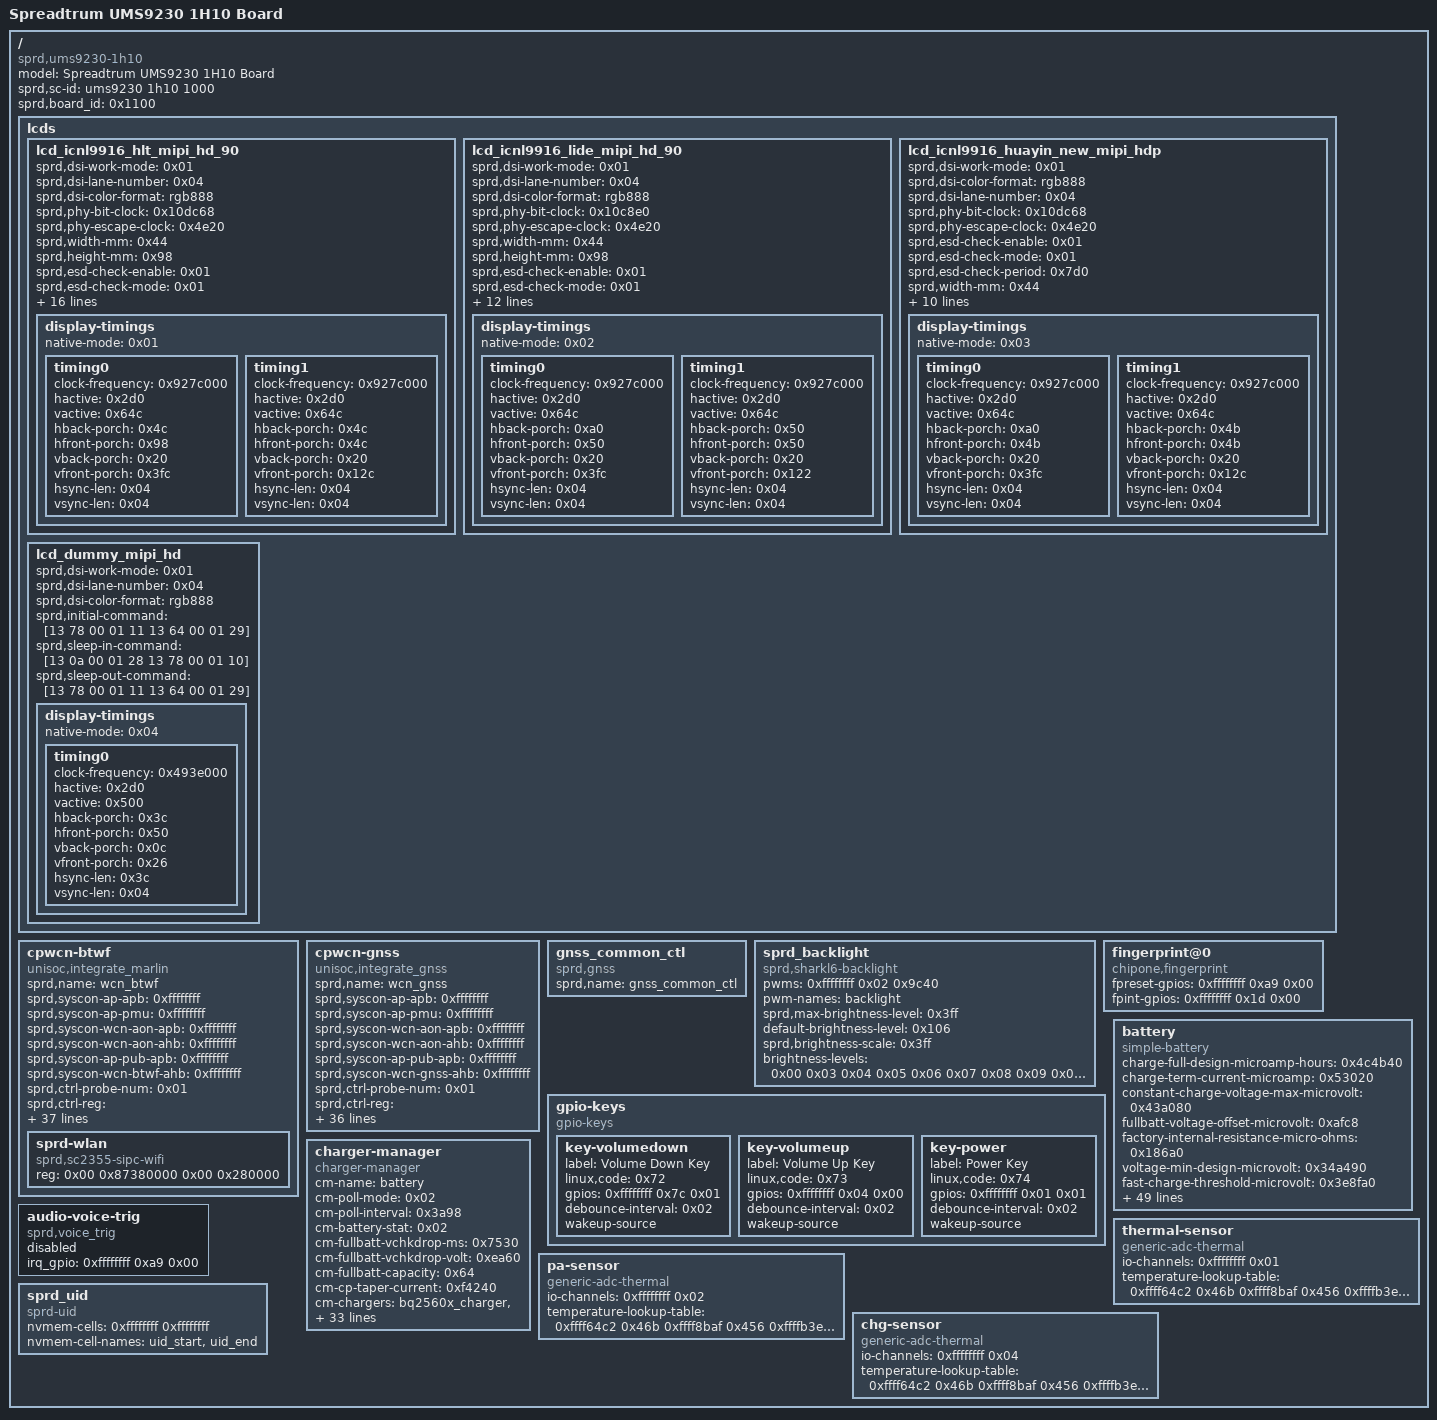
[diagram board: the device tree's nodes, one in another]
/dts-v1/;

/ {
	model = "Spreadtrum UMS9230 1H10 Board";
	compatible = "sprd,ums9230-1h10";
	sprd,sc-id = "ums9230 1h10 1000";
	sprd,board_id = <0x1100>;

	fragment {
		target-path = "/";

		__overlay__ {
			#address-cells = <0x02>;
			#size-cells = <0x02>;

			lcds {

				lcd_icnl9916_hlt_mipi_hd_90 {
					sprd,dsi-work-mode = <0x01>;
					sprd,dsi-lane-number = <0x04>;
					sprd,dsi-color-format = "rgb888";
					sprd,phy-bit-clock = <0x10dc68>;
					sprd,phy-escape-clock = <0x4e20>;
					sprd,width-mm = <0x44>;
					sprd,height-mm = <0x98>;
					sprd,esd-check-enable = <0x01>;
					sprd,esd-check-mode = <0x01>;
					sprd,esd-check-period = <0x3e8>;
					sprd,lcd-id-register = [a1];
					sprd,lcd-id-value-len = <0x01>;
					sprd,lcd-id-value = [99];
					sprd,lcd-id-tokernel = <0x9901>;
					sprd,lcd-id-adc-min = <0x1f4>;
					sprd,lcd-id-adc-max = <0x320>;
					sprd,reset-on-sequence = <0x01 0x05 0x00 0x05 0x01 0x78>;
					sprd,reset-off-sequence = <0x00 0x14>;
					sprd,initial-command = [39 00 00 04 f0 99 16 0c 39 00 00 15 c1 10 20 20 2c 04 30 30 04 4c 06 22 70 35 20 07 11 84 4c 00 93 39 00 00 07 c3 06 00 ff 00 ff 4d 39 00 00 0d c4 04 32 b8 40 00 bc 00 00 00 00 00 f0 39 00 00 18 c5 03 21 96 c8 3e 00 04 01 14 04 0e 1f c6 03 64 ff 01 04 18 22 45 14 38 39 00 00 0e c6 89 24 17 2b 2b 28 3f 03 16 16 00 00 00 39 00 00 1e b2 03 02 97 98 99 99 8b 01 49 65 71 65 71 65 71 65 71 65 71 65 71 00 00 00 55 55 00 00 00 39 00 00 1a b3 f3 01 02 15 95 89 00 00 7f 00 00 00 00 08 44 f3 01 01 01 01 00 00 00 00 00 39 00 00 21 b5 00 04 06 00 00 00 00 00 00 c1 00 2a 1a 18 16 14 12 10 0e 0c 0a 28 60 ff fc 00 00 00 00 00 00 00 39 00 00 21 b6 00 05 07 00 00 00 00 00 00 c1 00 2b 1b 19 17 15 13 11 0f 0d 0b 29 60 ff fc 00 00 00 00 00 00 00 39 00 00 17 b7 0a 0a 0a 0a 0a 0a 0a 0a 0a 0a 0a 0a 0a 0a 0a 0a 0a 0a 0a 0a 0a 0a 39 00 00 14 bc 00 00 00 00 04 00 ff f0 0b 33 5c 5b 33 33 00 64 3c 5e 36 39 00 00 0a bf 0c 19 0c 19 00 11 04 18 50 39 00 00 15 c0 40 93 ff ff ff 3f ff 00 ff 00 cc b1 23 45 67 89 ad ff ff f0 39 00 00 21 c7 76 54 32 22 23 45 67 76 30 76 54 32 22 23 45 67 76 30 31 00 01 ff ff 40 6e 6e 40 00 00 00 00 00 39 00 00 21 80 ff f9 ee e7 e0 d8 d6 d2 ce c2 ba b2 ab a5 9f 95 8c 85 7d 7d 74 6b 60 54 46 32 28 1c 19 15 11 0e 39 00 00 21 81 ff f9 ee e7 e0 d8 d6 d2 ce c2 ba b2 ab a5 9f 95 8c 85 7d 7d 74 6b 60 54 46 32 28 1c 19 15 11 0e 39 00 00 21 82 ff f9 ee e7 e0 d8 d6 d2 ce c2 ba b2 ab a5 9f 95 8c 85 7d 7d 74 6b 60 54 46 32 28 1c 19 15 11 0e 39 00 00 1a 83 01 0a 05 01 00 0a 05 01 00 0a 05 01 00 0a 06 02 00 0a 06 02 00 0a 06 02 00 39 00 00 1c 84 28 85 b2 da d8 4b 61 3c 70 07 e0 b2 da d8 4b 61 3c 70 07 e0 b2 da d8 4b 61 3c 70 15 00 00 0b c2 11 65 01 10 00 01 80 02 21 43 15 00 00 02 ca 01 39 00 00 04 f0 00 00 00 39 00 00 03 35 00 00 39 78 00 03 11 00 00 39 32 00 03 29 00 00 39 00 00 03 6d 02 00];
					sprd,sleep-in-command = [23 00 00 02 26 08 23 23 00 02 28 00 23 78 00 02 10 00];
					sprd,sleep-out-command = [23 78 00 02 11 00 23 23 00 02 29 00 23 00 00 02 26 01];
					phandle = <0x15>;

					display-timings {
						native-mode = <0x01>;

						timing0 {
							clock-frequency = <0x927c000>;
							hactive = <0x2d0>;
							vactive = <0x64c>;
							hback-porch = <0x4c>;
							hfront-porch = <0x98>;
							vback-porch = <0x20>;
							vfront-porch = <0x3fc>;
							hsync-len = <0x04>;
							vsync-len = <0x04>;
							phandle = <0x01>;
						};

						timing1 {
							clock-frequency = <0x927c000>;
							hactive = <0x2d0>;
							vactive = <0x64c>;
							hback-porch = <0x4c>;
							hfront-porch = <0x4c>;
							vback-porch = <0x20>;
							vfront-porch = <0x12c>;
							hsync-len = <0x04>;
							vsync-len = <0x04>;
							phandle = <0x16>;
						};
					};
				};

				lcd_icnl9916_lide_mipi_hd_90 {
					sprd,dsi-work-mode = <0x01>;
					sprd,dsi-lane-number = <0x04>;
					sprd,dsi-color-format = "rgb888";
					sprd,phy-bit-clock = <0x10c8e0>;
					sprd,phy-escape-clock = <0x4e20>;
					sprd,width-mm = <0x44>;
					sprd,height-mm = <0x98>;
					sprd,esd-check-enable = <0x01>;
					sprd,esd-check-mode = <0x01>;
					sprd,esd-check-period = <0x3e8>;
					sprd,reset-on-sequence = <0x01 0x05 0x00 0x0a 0x01 0x1e>;
					sprd,reset-off-sequence = <0x01 0x14>;
					sprd,initial-command = <0x39000003 0xf05a5939 0x3f1 0xa5a62300 0x2d431 0x39000005 0xc0409300 0x1f390000 0x21c11020 0x25220450 0x50044c06 0x22703030 0x711844c 0x931363 0x00 0x00 0x2300 0x2c200 0x39000009 0xc30600ff 0xff404d 0x1390000 0x21c40433 0xb840c0bc 0xa00000 0x264891 0xb3750004 0xe020f000 0x00 0x00 0x3900 0x21c503 0x2396c832 0x50212 0xc04323f 0x801100c 0x18c8000a 0x14011438 0x7f000000 0x39 0x21c6 0x8924172b 0x2b283f03 0x16160001 0x40009898 0x60801b00 0x00 0x00 0x00 0x39000021 0xca3d4001 0x19469441 0x8f33114a 0x5e2c4050 0x64324633 0x1010a 0x2220005 0x5032 0x4390000 0x21b28182 0x85864444 0x1019968 0x68686868 0x68686868 0x68686801 0x1010055 0x55102011 0x3900 0x21b3f2 0x1020581 0x68010168 0x1000008 0x4400008a 0xaa800000 0x00 0xffff0 0x39 0x21b6 0x282a00 0x00 0xc100 0x1a181614 0x12100e0c 0xa04607f 0xfc000000 0x00 0x39000021 0xb700292b 0x00 0xc1 0x1b1917 0x1513110f 0xd0b0560 0x7ffc0000 0x00 0x390000 0x21b90055 0x55555555 0x55555555 0x555550aa 0xaaaaaaaa 0xa0aaaaaa 0xaaaaa000 0x00 0x3900 0x9bb01 0x2030a04 0x13145239 0x21bc 0x00 0x400fff0 0xb33505b 0x33330000 0x00 0x00 0x00 0x00 0x39000007 0xbda1a252 0x2e008f39 0x11be 0xc884338 0x33000038 0xb2afb2 0xaf000033 0x3900000a 0xbf0c190c 0x19001104 0x18503900 0x21c776 0x54322223 0x45677630 0x76543222 0x23456776 0x30310001 0xffff00dc 0xdc400000 0x39 0x3fb 0x4a2c3900 0x3f0a5 0xa6390000 0x3f15a59 0x39000003 0x35000039 0x78000311 0x390a 0x32900 0x390000 0x36d0200>;
					sprd,vref-command = [39 00 00 03 f0 5a 59 39 00 00 03 f1 a5 a6 39 00 00 09 bb 01 02 03 0a 04 13 14 52];
					sprd,sleep-in-command = <0x39000003 0xf05a5939 0x3f1 0xa5a63900 0x9bb01 0x2030a04 0x13140039 0x36d 0x2500390a 0x32800 0x397800 0x3100000>;
					sprd,sleep-out-command = [39 00 00 03 f0 5a 59 39 00 00 03 f1 a5 a6 39 78 00 03 11 00 00 39 32 00 03 29 00 00 39 00 00 03 6d 02 00];
					phandle = <0x17>;

					display-timings {
						native-mode = <0x02>;

						timing0 {
							clock-frequency = <0x927c000>;
							hactive = <0x2d0>;
							vactive = <0x64c>;
							hback-porch = <0xa0>;
							hfront-porch = <0x50>;
							vback-porch = <0x20>;
							vfront-porch = <0x3fc>;
							hsync-len = <0x04>;
							vsync-len = <0x04>;
							phandle = <0x02>;
						};

						timing1 {
							clock-frequency = <0x927c000>;
							hactive = <0x2d0>;
							vactive = <0x64c>;
							hback-porch = <0x50>;
							hfront-porch = <0x50>;
							vback-porch = <0x20>;
							vfront-porch = <0x122>;
							hsync-len = <0x04>;
							vsync-len = <0x04>;
							phandle = <0x18>;
						};
					};
				};

				lcd_icnl9916_huayin_new_mipi_hdp {
					sprd,dsi-work-mode = <0x01>;
					sprd,dsi-color-format = "rgb888";
					sprd,dsi-lane-number = <0x04>;
					sprd,phy-bit-clock = <0x10dc68>;
					sprd,phy-escape-clock = <0x4e20>;
					sprd,esd-check-enable = <0x01>;
					sprd,esd-check-mode = <0x01>;
					sprd,esd-check-period = <0x7d0>;
					sprd,width-mm = <0x44>;
					sprd,height-mm = <0x97>;
					sprd,reset-on-sequence = <0x01 0x05 0x00 0x0a 0x01 0x14>;
					sprd,reset-off-sequence = <0x01 0x0a>;
					sprd,initial-command = <0x39000003 0xf05a5939 0x3f1 0xa5a63900 0x2d431 0x39000005 0xc0409300 0x1f390000 0x21c11020 0x202c044b 0x4b044c06 0x22703020 0x711844c 0x931363 0x00 0x00 0x3900 0x2c200 0x39000009 0xc30600ff 0xff404d 0x1390000 0x21c40433 0xb840c0bc 0xa00000 0x264891 0xb3750004 0xe020f000 0x00 0x00 0x3900 0x21c503 0x2396c832 0x50212 0xc04323f 0x801100c 0x1fc8000a 0x14011438 0x7f000000 0x39 0x21c6 0x8924172b 0x2b283f03 0x16160001 0x40009898 0x60801b00 0x00 0x00 0x00 0x39000021 0xca014000 0x19469441 0x8f331150 0x505a5a64 0x64323211 0x1010a 0x5220005 0x643c 0x4390000 0x21b20302 0x97989999 0x8b014965 0x71657165 0x71657165 0x71657100 0x55 0x55102011 0x3900 0xcb3f3 0x1011595 0x76000071 0x3900 0x21b600 0x4060000 0x00 0xc1002a1a 0x18161412 0x100e0c0a 0x2860fffc 0x00 0x39 0x21b7 0x50700 0x00 0xc1002b 0x1b191715 0x13110f0d 0xb2960ff 0xfc000000 0x00 0x39000021 0xb9005555 0x55555555 0x55555555 0x5550aaaa 0xaaaaaaa0 0xaaaaaaaa 0xaaa00000 0x00 0x390000 0x9bb0102 0x30a0413 0x14523900 0x21bc00 0x04 0xfff00b 0x33505b33 0x33000000 0x00 0x00 0x00 0x39 0x7bd 0xa1a2522e 0x8f3900 0x11be0c 0x88433833 0x3800 0xb2afb2af 0x3339 0xabf 0xc190c19 0x110418 0x50390000 0x21c77654 0x32222345 0x67763076 0x54322223 0x45677630 0x310001ff 0xff00dcdc 0x40000000 0x3900 0x2180ff 0xf6eae2db 0xd6d1cdc9 0xbeb5a599 0x8f877f76 0x756c6359 0x4e402e24 0x1916130f 0xc080439 0x2181 0xfff6eae2 0xdbd6d1cd 0xc9beb5a5 0x998f877f 0x76756c63 0x594e402e 0x24191613 0xf0c0804 0x39000021 0x82fff6ea 0xe2dbd6d1 0xcdc9beb5 0xa5998f87 0x7f76756c 0x63594e40 0x2e241916 0x130f0c08 0x4390000 0xe830101 0x10001 0x20002 0x20039 0x1c84 0x1489c3a6 0x7a90a4a9 0x701489c3 0xa67a90a4 0xa9701489 0xc3a67a90 0xa4a97039 0x3fb 0x5e403900 0x4c847 0x483900 0x33500 0x390000 0x3f15a59 0x39000003 0xf0a5a639 0x78000311 0x390a 0x32900 0x390000 0x36d0200>;
					sprd,sleep-in-command = [39 00 00 03 f0 5a 59 39 00 00 03 f1 a5 a6 39 00 00 09 bb 01 02 03 0a 04 13 14 00 39 00 00 03 f1 5a 59 39 00 00 03 f0 a5 a6 39 00 00 03 6d 25 00 39 0a 00 03 28 00 00 39 78 00 03 10 00 00];
					sprd,sleep-out-command = [39 78 00 03 11 00 00 39 0a 00 03 29 00 00 39 00 00 03 6d 02 00];
					phandle = <0x19>;

					display-timings {
						native-mode = <0x03>;

						timing0 {
							clock-frequency = <0x927c000>;
							hactive = <0x2d0>;
							vactive = <0x64c>;
							hback-porch = <0xa0>;
							hfront-porch = <0x4b>;
							vback-porch = <0x20>;
							vfront-porch = <0x3fc>;
							hsync-len = <0x04>;
							vsync-len = <0x04>;
							phandle = <0x03>;
						};

						timing1 {
							clock-frequency = <0x927c000>;
							hactive = <0x2d0>;
							vactive = <0x64c>;
							hback-porch = <0x4b>;
							hfront-porch = <0x4b>;
							vback-porch = <0x20>;
							vfront-porch = <0x12c>;
							hsync-len = <0x04>;
							vsync-len = <0x04>;
							phandle = <0x1a>;
						};
					};
				};

				lcd_dummy_mipi_hd {
					sprd,dsi-work-mode = <0x01>;
					sprd,dsi-lane-number = <0x04>;
					sprd,dsi-color-format = "rgb888";
					sprd,initial-command = [13 78 00 01 11 13 64 00 01 29];
					sprd,sleep-in-command = [13 0a 00 01 28 13 78 00 01 10];
					sprd,sleep-out-command = [13 78 00 01 11 13 64 00 01 29];
					phandle = <0x1b>;

					display-timings {
						native-mode = <0x04>;

						timing0 {
							clock-frequency = <0x493e000>;
							hactive = <0x2d0>;
							vactive = <0x500>;
							hback-porch = <0x3c>;
							hfront-porch = <0x50>;
							vback-porch = <0x0c>;
							vfront-porch = <0x26>;
							hsync-len = <0x3c>;
							vsync-len = <0x04>;
							phandle = <0x04>;
						};
					};
				};
			};

			cpwcn-btwf {
				compatible = "unisoc,integrate_marlin";
				sprd,name = "wcn_btwf";
				sprd,syscon-ap-apb = <0xffffffff>;
				sprd,syscon-ap-pmu = <0xffffffff>;
				sprd,syscon-wcn-aon-apb = <0xffffffff>;
				sprd,syscon-wcn-aon-ahb = <0xffffffff>;
				sprd,syscon-ap-pub-apb = <0xffffffff>;
				sprd,syscon-wcn-btwf-ahb = <0xffffffff>;
				sprd,ctrl-probe-num = <0x01>;
				sprd,ctrl-reg = <0x9018 0x23a8 0x2818 0x23a8 0x90 0x98 0x0c 0x1410 0x4c 0x0c>;
				sprd,ctrl-mask = <0x3fff 0x2000000 0x80 0x1000000 0x40000000 0x100f 0x55 0x3000000 0xffffffff 0x55>;
				sprd,ctrl-value = <0x70 0x2000000 0x80 0x1000000 0x40000000 0x00 0x55 0x3000000 0x7fdc00 0x00>;
				sprd,ctrl-rw-offset = <0x1000 0x2000 0x2000 0x2000 0x00 0x00 0x00 0x1000 0x00 0x00>;
				sprd,ctrl-us-delay = <0x3e8 0x3e8 0x3e8 0x7d0 0x3e8 0x3e8 0x3e8 0x3e8 0x3e8 0x3e8>;
				sprd,ctrl-type = <0x02 0x01 0x01 0x01 0x0a 0x0a 0x09 0x07 0x09 0x09>;
				sprd,ctrl-shutdown-reg = <0x98>;
				sprd,ctrl-shutdown-mask = <0x1000>;
				sprd,ctrl-shutdown-value = <0x1000>;
				sprd,ctrl-shutdown-rw-offset = <0x00>;
				sprd,ctrl-shutdown-us-delay = <0x0a>;
				sprd,ctrl-shutdown-type = <0x0a>;
				reg = <0x00 0x87000000 0x00 0x200000 0x00 0x7c00a000 0x00 0x74>;
				sprd,debugbus-to-ddr-disable;
				sprd,wcn-pm-qos-enable;
				sprd,file-name = "/dev/block/platform/soc/soc:ap-apb/201d0000.sdio/by-name/wcnmodem";
				sprd,file-name-ufs = "/dev/block/platform/soc/soc:ap-apb/20200000.ufs/by-name/wcnmodem";
				sprd,firmware-path = "/vendor/firmware/";
				sprd,file-length = <0x200000>;
				sprd,apcp-sync-addr = <0x7fdc00>;
				sprd,wcn-sipc-ver = <0x01>;
				vddwcn-supply = <0xffffffff>;
				dcxo1v8-supply = <0xffffffff>;
				vddwifipa-supply = <0xffffffff>;
				merlion-chip-en-gpios = <0xffffffff 0x76 0x00>;
				merlion-rst-gpios = <0xffffffff 0x75 0x00>;
				xtal-26m-type-sel-gpios = <0xffffffff 0xad 0x00>;
				nvmem-cells = <0xffffffff>;
				nvmem-cell-names = "wcn_efuse_blk0";
				#address-cells = <0x02>;
				#size-cells = <0x02>;
				phandle = <0x1c>;

				sprd-wlan {
					compatible = "sprd,sc2355-sipc-wifi";
					reg = <0x00 0x87380000 0x00 0x280000>;
				};
			};

			cpwcn-gnss {
				compatible = "unisoc,integrate_gnss";
				sprd,name = "wcn_gnss";
				sprd,syscon-ap-apb = <0xffffffff>;
				sprd,syscon-ap-pmu = <0xffffffff>;
				sprd,syscon-wcn-aon-apb = <0xffffffff>;
				sprd,syscon-wcn-aon-ahb = <0xffffffff>;
				sprd,syscon-ap-pub-apb = <0xffffffff>;
				sprd,syscon-wcn-gnss-ahb = <0xffffffff>;
				sprd,ctrl-probe-num = <0x01>;
				sprd,ctrl-reg = <0x9018 0x23a8 0x2818 0x23a8 0x90 0xc8 0x0c 0x1404 0x50 0x0c>;
				sprd,ctrl-mask = <0x3fff 0x2000000 0x80 0x1000000 0x40000000 0x100f 0x22 0x1ffffff 0xffffffff 0x22>;
				sprd,ctrl-value = <0x70 0x2000000 0x80 0x1000000 0x40000000 0x00 0x22 0x1600000 0x1ffc00 0x00>;
				sprd,ctrl-rw-offset = <0x1000 0x2000 0x2000 0x2000 0x00 0x00 0x00 0x1000 0x00 0x00>;
				sprd,ctrl-us-delay = <0x3e8 0x3e8 0x3e8 0x7d0 0x3e8 0x3e8 0x3e8 0x3e8 0x3e8 0x3e8>;
				sprd,ctrl-type = <0x02 0x01 0x01 0x01 0x0a 0x0a 0x09 0x08 0x09 0x09>;
				sprd,ctrl-shutdown-reg = <0xc8>;
				sprd,ctrl-shutdown-mask = <0x1000>;
				sprd,ctrl-shutdown-value = <0x1000>;
				sprd,ctrl-shutdown-rw-offset = <0x00>;
				sprd,ctrl-shutdown-us-delay = <0x0a>;
				sprd,ctrl-shutdown-type = <0x0a>;
				reg = <0x00 0x87600000 0x00 0x180000>;
				sprd,file-name = "/dev/block/platform/soc/soc:ap-apb/201d0000.sdio/by-name/gnssmodem";
				sprd,file-name-ext = "/dev/block/platform/soc/soc:ap-apb/201d0000.sdio/by-name/gnssmodem";
				sprd,file-name-ufs = "/dev/block/platform/soc/soc:ap-apb/20200000.ufs/by-name/gnssmodem";
				sprd,file-name-ext-ufs = "/dev/block/platform/soc/soc:ap-apb/20200000.ufs/by-name/gnssmodem";
				sprd,file-length = <0x180000>;
				sprd,apcp-sync-addr = <0x1ffc00>;
				sprd,wcn-sipc-ver = <0x01>;
				vddwcn-supply = <0xffffffff>;
				dcxo1v8-supply = <0xffffffff>;
				merlion-chip-en-gpios = <0xffffffff 0x76 0x00>;
				merlion-rst-gpios = <0xffffffff 0x75 0x00>;
				xtal-26m-type-sel-gpios = <0xffffffff 0xad 0x00>;
				#address-cells = <0x01>;
				#size-cells = <0x01>;
				nvmem-cells = <0xffffffff>;
				nvmem-cell-names = "gnss_efuse_blk0";
				phandle = <0x1d>;
			};

			gnss_common_ctl {
				compatible = "sprd,gnss";
				sprd,name = "gnss_common_ctl";
			};

			sprd_backlight {
				compatible = "sprd,sharkl6-backlight";
				pwms = <0xffffffff 0x02 0x9c40>;
				pwm-names = "backlight";
				sprd,max-brightness-level = <0x3ff>;
				default-brightness-level = <0x106>;
				sprd,brightness-scale = <0x3ff>;
				brightness-levels = <0x00 0x03 0x04 0x05 0x06 0x07 0x08 0x09 0x0a 0x0b 0x0c 0x0d 0x0e 0x10 0x11 0x12 0x13 0x14 0x15 0x16 0x17 0x18 0x19 0x1a 0x1b 0x1c 0x1d 0x1f 0x21 0x23 0x25 0x27 0x29 0x2b 0x2d 0x2f 0x30 0x32 0x34 0x36 0x38 0x3a 0x3c 0x3e 0x40 0x43 0x45 0x48 0x4a 0x4c 0x4e 0x50 0x52 0x54 0x56 0x58 0x5a 0x5c 0x5e 0x60 0x62 0x64 0x66 0x68 0x6b 0x6d 0x70 0x72 0x74 0x76 0x78 0x7a 0x7c 0x7e 0x80 0x82 0x84 0x86 0x88 0x8a 0x8c 0x8e 0x90 0x93 0x95 0x97 0x9a 0x9c 0x9e 0xa0 0xa2 0xa4 0xa6 0xa8 0xaa 0xac 0xaf 0xb2 0xb5 0xb8 0xbb 0xbe 0xc1 0xc4 0xc7 0xcb 0xcd 0xd0 0xd3 0xd6 0xd9 0xdc 0xdf 0xe2 0xe5 0xea 0xed 0xf0 0xf3 0xf7 0xfa 0xfd 0x100 0x103 0x107 0x10a 0x10d 0x10e 0x112 0x115 0x118 0x11b 0x11f 0x122 0x126 0x129 0x12c 0x12f 0x133 0x136 0x13a 0x13e 0x145 0x149 0x14e 0x153 0x154 0x157 0x15b 0x15e 0x162 0x166 0x16d 0x171 0x176 0x17c 0x17e 0x181 0x185 0x188 0x18c 0x190 0x197 0x19b 0x1a0 0x1a6 0x1aa 0x1ae 0x1b2 0x1b6 0x1ba 0x1be 0x1c4 0x1c9 0x1cc 0x1d0 0x1d6 0x1da 0x1e0 0x1e6 0x1ec 0x1f2 0x1f8 0x1fc 0x200 0x204 0x20a 0x20f 0x214 0x218 0x21c 0x221 0x226 0x22b 0x231 0x238 0x23e 0x243 0x248 0x24d 0x252 0x258 0x25d 0x262 0x267 0x26c 0x271 0x276 0x27b 0x281 0x287 0x28c 0x291 0x296 0x29b 0x2a1 0x2b0 0x2b6 0x2bc 0x2c2 0x2c8 0x2cc 0x2d0 0x2d5 0x2da 0x2df 0x2e4 0x2ea 0x2f0 0x2f6 0x2fc 0x302 0x308 0x30e 0x316 0x31e 0x32a 0x334 0x33e 0x348 0x352 0x35c 0x366 0x370 0x37a 0x384 0x398 0x3ac 0x3b6 0x3c0 0x3ca 0x3d4 0x3de 0x3f2 0x3fc 0x3ff>;
				phandle = <0x0a>;
			};

			fingerprint@0 {
				compatible = "chipone,fingerprint";
				fpreset-gpios = <0xffffffff 0xa9 0x00>;
				fpint-gpios = <0xffffffff 0x1d 0x00>;
			};

			gpio-keys {
				compatible = "gpio-keys";

				key-volumedown {
					label = "Volume Down Key";
					linux,code = <0x72>;
					gpios = <0xffffffff 0x7c 0x01>;
					debounce-interval = <0x02>;
					wakeup-source;
				};

				key-volumeup {
					label = "Volume Up Key";
					linux,code = <0x73>;
					gpios = <0xffffffff 0x04 0x00>;
					debounce-interval = <0x02>;
					wakeup-source;
				};

				key-power {
					label = "Power Key";
					linux,code = <0x74>;
					gpios = <0xffffffff 0x01 0x01>;
					debounce-interval = <0x02>;
					wakeup-source;
				};
			};

			battery {
				compatible = "simple-battery";
				charge-full-design-microamp-hours = <0x4c4b40>;
				charge-term-current-microamp = <0x53020>;
				constant-charge-voltage-max-microvolt = <0x43a080>;
				fullbatt-voltage-offset-microvolt = <0xafc8>;
				factory-internal-resistance-micro-ohms = <0x186a0>;
				voltage-min-design-microvolt = <0x34a490>;
				fast-charge-threshold-microvolt = <0x3e8fa0>;
				fullbatt-voltage = <0x42c1d8>;
				fullbatt-current = <0x53020>;
				fullbatt-track-end-vol = <0x418958>;
				fullbatt-track-end-cur = <0x1fbd0>;
				first-calib-voltage = <0x369a84>;
				first-calib-capacity = <0x32>;
				ir-us-upper-limit-microvolt = <0x44aa20>;
				ir-cv-offset-microvolt = <0x186a0>;
				ir-rc-micro-ohms = <0x4e20>;
				ocv-capacity-celsius = <0x19>;
				ocv-capacity-table-0 = <0x42ae50 0x64 0x4215f8 0x5f 0x413b38 0x5a 0x405c90 0x55 0x3f81d0 0x50 0x3eb2c8 0x4b 0x3dff18 0x46 0x3d0518 0x41 0x3c70a8 0x3c 0x3b9db8 0x37 0x3aedf0 0x32 0x3a8860 0x2d 0x3a3270 0x28 0x39f008 0x23 0x39b188 0x1e 0x397308 0x19 0x38dab0 0x14 0x387138 0x0f 0x37fff0 0x0a 0x369c78 0x05 0x33e140 0x00>;
				voltage-temp-table = <0x104410 0x320 0xea218 0x352 0xd0bd8 0x384 0xb8150 0x3b6 0xa1220 0x3e8 0x8c230 0x41a 0x79568 0x44c 0x687e0 0x47e 0x59d80 0x4b0 0x4ce78 0x4e2 0x41eb0 0x514 0x38a40 0x546 0x30958 0x578 0x29bf8 0x5aa 0x23a50 0x5dc 0x1ec30 0x60e 0x1a5e0 0x640 0x16f30 0x672>;
				capacity-temp-table = <0x2d 0x64 0x19 0x64 0x0a 0x64 0x00 0x5f 0xfffffff6 0x5a>;
				resistance-temp-table = <0x2d 0x35 0x19 0x64 0x0a 0x18b 0x00 0x237 0xfffffff6 0x319>;
				charge-sdp-current-microamp = <0x7a120 0x7a120>;
				charge-dcp-current-microamp = <0x1e8480 0x1e8480>;
				charge-cdp-current-microamp = <0x16e360 0x16e360>;
				charge-unknown-current-microamp = <0x7a120 0x7a120>;
				charge-fchg-current-microamp = <0x33e140 0x4c4b40>;
				charge-flash-current-microamp = <0x4c4b40 0x2932e0>;
				charge-wl-bpp-current-microamp = <0xf4240 0xf4240>;
				charge-wl-epp-current-microamp = <0x1e8480 0xf4240>;
				cap-calib-energy-density-ocv-table = <0x331df0 0x39fbc0 0x3f52f0 0x426030>;
				cap-track-energy-density-ocv-table = <0x33e140 0x38cb10>;
				dcp-jeita-temp-table = <0x3e8 0x406 0x00 0x43a080 0x47e 0x49c 0xf4240 0x43a080 0x5aa 0x58c 0x1e8480 0x43a080 0x60e 0x5f0 0x155cc0 0x3eddc0>;
				sdp-jeita-temp-table = <0x3e8 0x406 0x00 0x43a080 0x47e 0x49c 0x7a120 0x43a080 0x5aa 0x58c 0x7a120 0x43a080 0x60e 0x5f0 0x7a120 0x3eddc0>;
				cdp-jeita-temp-table = <0x3e8 0x406 0x00 0x43a080 0x47e 0x49c 0xaae60 0x43a080 0x5aa 0x58c 0x16e360 0x43a080 0x60e 0x5f0 0xaae60 0x3eddc0>;
				unknown-jeita-temp-table = <0x3e8 0x406 0x00 0x43a080 0x47e 0x49c 0x7a120 0x43a080 0x5aa 0x58c 0x7a120 0x43a080 0x60e 0x5f0 0x7a120 0x3eddc0>;
				fchg-jeita-temp-table = <0x3e8 0x406 0x00 0x43a080 0x47e 0x49c 0x16e360 0x43a080 0x5aa 0x58c 0x33e140 0x43a080 0x60e 0x5f0 0x2191c0 0x3eddc0>;
				wl-bpp-jeita-temp-table = <0x3e8 0x406 0x00 0x43a080 0x47e 0x49c 0x7a120 0x43a080 0x5aa 0x58c 0xf4240 0x43a080 0x60e 0x5f0 0x4c4b40 0x43a080>;
				wl-epp-jeita-temp-table = <0x3e8 0x406 0x00 0x43a080 0x47e 0x49c 0x7a120 0x43a080 0x5aa 0x58c 0x1e8480 0x43a080 0x60e 0x5f0 0x7a120 0x43a080>;
				phandle = <0x05>;
			};

			charger-manager {
				compatible = "charger-manager";
				cm-name = "battery";
				cm-poll-mode = <0x02>;
				cm-poll-interval = <0x3a98>;
				cm-battery-stat = <0x02>;
				cm-fullbatt-vchkdrop-ms = <0x7530>;
				cm-fullbatt-vchkdrop-volt = <0xea60>;
				cm-fullbatt-capacity = <0x64>;
				cm-cp-taper-current = <0xf4240>;
				cm-chargers = "bq2560x_charger", "eta6937_slave_charger";
				cm-fuel-gauge = "sc27xx-fgu";
				cm-battery-cold = <0xc8>;
				cm-battery-cold-in-minus;
				cm-battery-hot = <0x320>;
				cm-battery-temp-diff = <0x64>;
				cm-charging-max = <0x1499700>;
				cm-discharging-max = <0x2932e0>;
				cm-wdt-interval = <0x3c>;
				cm-shutdown-voltage = <0x2f4d60>;
				cm-tickle-time-out = <0x384>;
				cm-one-cap-time = <0x1e>;
				cm-thermal-zone = "board-thmzone";
				cm-charge-voltage-max = <0xa037a0>;
				cm-fast-charge-voltage-max = <0xa037a0>;
				cm-flash-charge-voltage-max = <0xb71b00>;
				cm-wireless-charge-voltage-max = <0x632ea0>;
				cm-wireless-fast-charge-voltage-max = <0xb71b00>;
				cm-charge-voltage-drop = <0xaae60>;
				cm-fast-charge-voltage-drop = <0xaae60>;
				cm-flash-charge-voltage-drop = <0xf4240>;
				cm-wireless-charge-voltage-drop = <0xaae60>;
				cm-wireless-fast-charge-voltage-drop = <0xf4240>;
				sprd,support-fchg;
				sprd,support-sfcp;
				sprd,pd-fixed-max-microwatt = <0x112a880>;
				cm-cap-remap-table = <0x00 0x01 0x04 0x02 0x14 0x02 0x62 0x63 0x02 0x63 0x64 0x02>;
				monitored-battery = <0x05>;
				cm-keep-awake;
				phys = <0xffffffff>;
				extcon = <0xffffffff 0xffffffff>;
				pd-extcon-enable;
			};

			thermal-sensor {
				compatible = "generic-adc-thermal";
				#thermal-sensor-cells = <0x00>;
				io-channels = <0xffffffff 0x01>;
				io-channel-names = "sensor-channel";
				temperature-lookup-table = <0xffff64c2 0x46b 0xffff8baf 0x456 0xffffb3e8 0x432 0xffffedb9 0x3d7 0x277e 0x346 0x60e5 0x28e 0xaf7a 0x19d 0xd677 0x13c 0xfd7f 0xee 0x12484 0xb2 0x14b93 0x85 0x172a3 0x64 0x199b0 0x4b 0x1c0c9 0x39 0x1e7c8 0x2b>;
				phandle = <0x06>;
			};

			pa-sensor {
				compatible = "generic-adc-thermal";
				#thermal-sensor-cells = <0x00>;
				io-channels = <0xffffffff 0x02>;
				io-channel-names = "sensor-channel";
				temperature-lookup-table = <0xffff64c2 0x46b 0xffff8baf 0x456 0xffffb3e8 0x432 0xffffedb9 0x3d7 0x277e 0x346 0x60e5 0x28e 0xaf7a 0x19d 0xd677 0x13c 0xfd7f 0xee 0x12484 0xb2 0x14b93 0x85 0x172a3 0x64 0x199b0 0x4b 0x1c0c9 0x39 0x1e7c8 0x2b>;
				phandle = <0x07>;
			};

			chg-sensor {
				compatible = "generic-adc-thermal";
				#thermal-sensor-cells = <0x00>;
				io-channels = <0xffffffff 0x04>;
				io-channel-names = "sensor-channel";
				temperature-lookup-table = <0xffff64c2 0x46b 0xffff8baf 0x456 0xffffb3e8 0x432 0xffffedb9 0x3d7 0x277e 0x346 0x60e5 0x28e 0xaf7a 0x19d 0xd677 0x13c 0xfd7f 0xee 0x12484 0xb2 0x14b93 0x85 0x172a3 0x64 0x199b0 0x4b 0x1c0c9 0x39 0x1e7c8 0x2b>;
				phandle = <0x08>;
			};

			audio-voice-trig {
				status = "disable";
				compatible = "sprd,voice_trig";
				irq_gpio = <0xffffffff 0xa9 0x00>;
			};

			sprd_uid {
				compatible = "sprd-uid";
				nvmem-cells = <0xffffffff 0xffffffff>;
				nvmem-cell-names = "uid_start", "uid_end";
			};
		};
	};

	fragment@0 {
		target = <0xffffffff>;

		__overlay__ {
			#address-cells = <0x01>;
			#size-cells = <0x00>;

			core@3 {
				compatible = "sprd,sipc";
				reg = <0x03>;
				label = "sipc-wcn";
				mboxes = <0xffffffff 0x08 0x00>;
				sprd,smem-info = <0x87240000 0x240000 0x140000>;
				phandle = <0x1e>;

				wcn_bt {
					compatible = "sprd,wcn_internal_chip";
					sprd,name = "ttyBT";
					sprd,dst = <0x03>;
					sprd,channel = <0x04>;
					sprd,tx_bufid = <0x0b>;
					sprd,rx_bufid = <0x0a>;
				};

				wcn_fm {
					compatible = "sprd,wcn_fm_internal_chip";
					sprd,name = "fm";
					sprd,dst = <0x03>;
					sprd,tx_channel = <0x04>;
					sprd,rx_channel = <0x04>;
					sprd,tx_bufid = <0x0e>;
					sprd,rx_bufid = <0x0d>;
				};
			};

			core@4 {
				compatible = "sprd,sipc";
				#address-cells = <0x01>;
				#size-cells = <0x00>;
				reg = <0x04>;
				label = "sipc-gnss";
				mboxes = <0xffffffff 0x09 0x00>;
				sprd,smem-info = <0x8749b000 0x11b000 0x32000>;
				phandle = <0x1f>;

				channel@4 {
					compatible = "sprd,spipe";
					reg = <0x04>;
					label = "sttygnss0";
					sprd,ringnr = <0x01>;
					sprd,size-rxbuf = <0x19000>;
					sprd,size-txbuf = <0xc800>;
					phandle = <0x20>;
				};
			};
		};
	};

	fragment@1 {
		target = <0xffffffff>;

		__overlay__ {
			bootargs_ext = "androidboot.hardware=ums9230_1h10 androidboot.dtbo_idx=0";
		};
	};

	fragment@2 {
		target = <0xffffffff>;

		__overlay__ {
			#address-cells = <0x02>;
			#size-cells = <0x02>;

			wcn-mem@87000000 {
				reg = <0x00 0x87000000 0x00 0x800000>;
				phandle = <0x21>;
			};

			logobuffer@9e000000 {
				reg = <0x00 0x9e000000 0x00 0xab0000>;
				phandle = <0x0b>;
			};

			oemcrypto@b6100000 {
				reg = <0x00 0xb6100000 0x00 0x1100000>;
				phandle = <0x14>;
			};

			widevine@df400000 {
				compatible = "shared-dma-pool";
				reg = <0x00 0xdf400000 0x00 0x10400000>;
				reusable;
				phandle = <0x22>;
			};

			faceid-mem@ffa70000 {
				reg = <0x00 0xffa70000 0x00 0x500000>;
				phandle = <0x13>;
			};
		};
	};

	fragment@3 {
		target = <0xffffffff>;

		__overlay__ {

			board-thmzone {
				polling-delay-passive = <0x00>;
				polling-delay = <0x00>;
				thermal-sensors = <0x06>;
				phandle = <0x23>;
			};

			pa-thmzone {
				polling-delay-passive = <0x00>;
				polling-delay = <0x00>;
				thermal-sensors = <0x07>;
				phandle = <0x24>;
			};

			chg-thmzone {
				polling-delay-passive = <0x00>;
				polling-delay = <0x00>;
				thermal-sensors = <0x08>;
				phandle = <0x25>;
			};
		};
	};

	fragment@4 {
		target = <0xffffffff>;

		__overlay__ {
			status = "okay";
			clock-frequency = <0x61a80>;
			#address-cells = <0x01>;
			#size-cells = <0x00>;

			sensor-main@20 {
				compatible = "sprd,sensor-main";
				reg = <0x20>;
				clock-names = "clk_src", "sensor_eb", "clk_96m", "clk_76m8", "clk_48m", "clk_26m";
				clocks = <0xffffffff 0x02 0xffffffff 0x0d 0xffffffff 0x04 0xffffffff 0x10 0xffffffff 0x05 0xffffffff>;
				vddio-supply = <0xffffffff>;
				vddcama-supply = <0xffffffff>;
				dvdd-gpios = <0xffffffff 0x71 0x00>;
				avdd-gpios = <0xffffffff 0x70 0x00>;
				vddcamd-supply = <0xffffffff>;
				vddcammot-supply = <0xffffffff>;
				reset-gpios = <0xffffffff 0x2d 0x00>;
				power-down-gpios = <0xffffffff 0x2f 0x00>;
				sprd,phyid = <0x00>;
				csi = <0xffffffff>;
				power-domains = <0xffffffff>;
				phandle = <0x26>;
			};
		};
	};

	fragment@5 {
		target = <0xffffffff>;

		__overlay__ {
			status = "okay";
			clock-frequency = <0x61a80>;
			#address-cells = <0x01>;
			#size-cells = <0x00>;

			sensor-sub@5a {
				compatible = "sprd,sensor-sub";
				reg = <0x5a>;
				clock-names = "clk_src", "sensor_eb", "clk_96m", "clk_76m8", "clk_48m", "clk_26m";
				clocks = <0xffffffff 0x02 0xffffffff 0x0d 0xffffffff 0x04 0xffffffff 0x10 0xffffffff 0x05 0xffffffff>;
				vddio-supply = <0xffffffff>;
				vddcama-supply = <0xffffffff>;
				dvdd-gpios = <0xffffffff 0x71 0x00>;
				avdd-gpios = <0xffffffff 0x70 0x00>;
				vddcamd-supply = <0xffffffff>;
				vddcammot-supply = <0xffffffff>;
				reset-gpios = <0xffffffff 0x2c 0x00>;
				power-down-gpios = <0xffffffff 0x89 0x00>;
				sprd,phyid = <0x02>;
				csi = <0xffffffff>;
				power-domains = <0xffffffff>;
				phandle = <0x27>;
			};
		};
	};

	fragment@6 {
		target = <0xffffffff>;

		__overlay__ {
			status = "okay";
			clock-frequency = <0x61a80>;
			#address-cells = <0x01>;
			#size-cells = <0x00>;

			sensor-main2@20 {
				compatible = "sprd,sensor-main2";
				reg = <0x20>;
				clock-names = "clk_src", "sensor_eb", "clk_96m", "clk_76m8", "clk_48m", "clk_26m";
				clocks = <0xffffffff 0x03 0xffffffff 0x0c 0xffffffff 0x04 0xffffffff 0x10 0xffffffff 0x05 0xffffffff>;
				vddio-supply = <0xffffffff>;
				vddcama-supply = <0xffffffff>;
				vddcamd-supply = <0xffffffff>;
				vddcammot-supply = <0xffffffff>;
				power-down-gpios = <0xffffffff 0x28 0x00>;
				reset-gpios = <0xffffffff 0x29 0x00>;
				sprd,phyid = <0x03>;
				csi = <0xffffffff>;
				power-domains = <0xffffffff>;
				phandle = <0x28>;
			};

			sensor-sub2@41 {
				compatible = "sprd,sensor-sub2";
				reg = <0x41>;
				clock-names = "clk_src", "sensor_eb", "clk_96m", "clk_76m8", "clk_48m", "clk_26m";
				clocks = <0xffffffff 0x03 0xffffffff 0x0c 0xffffffff 0x04 0xffffffff 0x10 0xffffffff 0x05 0xffffffff>;
				vddcama-supply = <0xffffffff>;
				vddcamd-supply = <0xffffffff>;
				vddcammot-supply = <0xffffffff>;
				sprd,phyid = <0x04>;
				csi = <0xffffffff>;
				phandle = <0x29>;
			};

			sensor-main3@61 {
				compatible = "sprd,sensor-main3";
				reg = <0x61>;
				clock-names = "clk_src", "sensor_eb", "clk_96m", "clk_76m8", "clk_48m", "clk_26m";
				clocks = <0xffffffff 0x03 0xffffffff 0x0c 0xffffffff 0x04 0xffffffff 0x10 0xffffffff 0x05 0xffffffff>;
				vddcama-supply = <0xffffffff>;
				vddcamd-supply = <0xffffffff>;
				vddcammot-supply = <0xffffffff>;
				sprd,phyid = <0x03>;
				csi = <0xffffffff>;
				phandle = <0x2a>;
			};
		};
	};

	fragment@7 {
		target = <0xffffffff>;

		__overlay__ {
			status = "okay";
			clock-frequency = <0x61a80>;
			#address-cells = <0x01>;
			#size-cells = <0x00>;

			charger@6a {
				compatible = "eta,eta6937_slave_chg";
				reg = <0x6a>;
				phys = <0xffffffff>;
				monitored-battery = <0x05>;
				extcon = <0xffffffff>;
				enable-gpio = <0xffffffff 0xac 0x00>;
				role = <0x02>;
				phandle = <0x2b>;
			};

			flash-ic@63 {
				compatible = "sprd,flash-ocp81375";
				reg = <0x63>;
				sprd,flash-ic = <0x13ddf>;
				sprd,torch = <0x01>;
				sprd,preflash = <0x01>;
				sprd,highlight = <0x01>;
				sprd,torch-level = <0x80>;
				sprd,preflash-level = <0x80>;
				sprd,highlight-level = <0x80>;
				sprd,lvfm-enable = <0x01>;
				flash-torch-en-gpios = <0xffffffff 0x8b 0x00>;
				flash-chip-en-gpios = <0xffffffff 0x8a 0x00>;
				phandle = <0x2c>;
			};
		};
	};

	fragment@8 {
		target = <0xffffffff>;

		__overlay__ {
			status = "okay";
			clock-frequency = <0x61a80>;
			#address-cells = <0x01>;
			#size-cells = <0x00>;

			charger@6b {
				compatible = "ti,bq2560x_chg";
				reg = <0x6b>;
				phys = <0xffffffff>;
				monitored-battery = <0x05>;
				extcon = <0xffffffff>;
				role = <0x01>;
				phandle = <0x2d>;

				otg-vbus {
					regulator-name = "vddvbus";
					phandle = <0x09>;
				};
			};
		};
	};

	fragment@9 {
		target = <0xffffffff>;

		__overlay__ {
			status = "okay";
			#address-cells = <0x01>;
			#size-cells = <0x00>;

			chipone_tddi@0 {
				status = "okay";
				compatible = "chipone_tddi";
				spi-max-frequency = <0x5b8d80>;
				reg = <0x00>;
				cs = <0x03>;
				interrupt-parent = <0xffffffff>;
				interrupts = <0x90 0x2000>;
				chipone,irq-gpio = <0xffffffff 0x90 0x00>;
				chipone,rst-gpio = <0xffffffff 0x91 0x00>;
				vdd_name = "vdd28";
				virtualkeys = <0x50 0x384 0x3c 0x28 0xf0 0x384 0x3c 0x28 0x190 0x384 0x3c 0x28>;
				chipone,x-res = <0x2d0>;
				chipone,y-res = <0x64c>;
				chipone,touch-charger-detect-enable;
				chipone,touch-charger-detect-type = "poll";
				chipone,touch-charger-detect-psy-name = "bq2560x_charger";
				chipone,touch-charger-detect-psp = "POWER_SUPPLY_PROP_ONLINE";
				chipone,touch-charger-detect-psp-poll-interval = <0x3e8>;
			};

			focaltech@1 {
				compatible = "focaltech,fts";
				reg = <0x01>;
				spi-max-frequency = <0x5b8d80>;
				interrupt-parent = <0xffffffff>;
				interrupts = <0x90 0x02>;
				focaltech,reset-gpio = <0xffffffff 0x91 0x00>;
				focaltech,irq-gpio = <0xffffffff 0x90 0x00>;
				focaltech,max-touch-number = <0x0a>;
				focaltech,display-coords = <0x00 0x00 0x2cf 0x63f>;
			};
		};
	};

	fragment@10 {
		target = <0xffffffff>;

		__overlay__ {
			vdd-supply = <0xffffffff>;
			extcon = <0xffffffff>;
			sprd,hsphy-device-eye-pattern = <0x63ad1c0>;
			sprd,hsphy-host-eye-pattern = <0x4f3d1c0>;
			status = "okay";
		};
	};

	fragment@11 {
		target = <0xffffffff>;

		__overlay__ {
			extcon = <0xffffffff 0xffffffff>;
			vbus-supply = <0x09>;
			status = "okay";
		};
	};

	fragment@12 {
		target = <0xffffffff>;

		__overlay__ {
			cd-gpios = <0xffffffff 0x23 0x00>;
		};
	};

	fragment@13 {
		target = <0xffffffff>;

		__overlay__ {
			status = "okay";
			#address-cells = <0x01>;
			#size-cells = <0x00>;
		};
	};

	fragment@14 {
		target = <0xffffffff>;

		__overlay__ {
			status = "okay";
			clock-frequency = <0xf4240>;
		};
	};

	fragment@15 {
		target = <0xffffffff>;

		__overlay__ {
			status = "okay";
		};
	};

	fragment@16 {
		target = <0xffffffff>;

		__overlay__ {
			status = "okay";
		};
	};

	fragment@17 {
		target = <0xffffffff>;

		__overlay__ {
			status = "okay";
			sprd,spk-ext-pa-info = <0x00 0x00 0x01 0x00>;
			sprd,spk-ext-pa-gpio = <0xffffffff 0x9c 0x00>;
		};
	};

	fragment@18 {
		target = <0xffffffff>;

		__overlay__ {
			regulator-always-on;
		};
	};

	fragment@19 {
		target = <0xffffffff>;

		__overlay__ {
			monitored-battery = <0x05>;
			sprd,calib-resistance-micro-ohms = <0x128e>;
			sprd,comp-resistance-mohm = <0x07>;
			fgu-capacity-track;
			phys = <0xffffffff>;
			sprd,relax-counter-threshold = <0x244>;
			sprd,relax-current-threshold = <0x1e>;
			sprd,capacity-sleep-calibration;
			sprd,capacity-boot-calibration;
			sprd,capacity-charge-cycle;
			sprd,basp;
		};
	};

	fragment@20 {
		target = <0xffffffff>;

		__overlay__ {
			sprd,backlight = <0x0a>;
			avdd-gpio = <0xffffffff 0x87 0x00>;
			avee-gpio = <0xffffffff 0x88 0x00>;
			reset-gpio = <0xffffffff 0x32 0x00>;
		};
	};

	fragment@21 {
		target = <0xffffffff>;

		__overlay__ {
			sprd,logo-memory = <0x0b>;
			sprd,backlight = <0x0a>;
		};
	};

	fragment@22 {
		target = <0xffffffff>;

		__overlay__ {
			status = "okay";
			sprd,input-voltage-microvolt = <0x4c4b40>;
			sprd,pd-fixed-max-microwatt = <0x112a880>;
			sprd,support-sfcp;
			phys = <0xffffffff>;
		};
	};

	fragment@23 {
		target = <0xffffffff>;

		__overlay__ {
			status = "okay";

			connector {
				compatible = "usb-c-connector";
				label = "USB-C";
				power-role = "dual";
				try-power-role = "sink";
				source-pdos = <0x4019028>;
				sink-pdos = <0x401912c>;
				op-sink-microwatt = <0x989680>;
				phandle = <0x2e>;
			};
		};
	};

	fragment@24 {
		target = <0xffffffff>;

		__overlay__ {
			sprd-scene = "boost", "lcdon", "lcdoff", "camlow", "camhigh", "camveryhigh", "faceid", "top", "boot-opt";
			sprd-freq = <0x535 0x300 0x100 0x535 0x535 0xbacd 0x535 0xbacd 0xbacd>;
		};
	};

	fragment@25 {
		target = <0xffffffff>;

		__overlay__ {
			pinctrl-names = "gpio_8", "gpio_22", "gpio_24", "gpio_25", "gpio_26", "gpio_124", "gpio_175";
			pinctrl-0 = <0x0c>;
			pinctrl-1 = <0x0d>;
			pinctrl-2 = <0x0e>;
			pinctrl-3 = <0x0f>;
			pinctrl-4 = <0x10>;
			pinctrl-5 = <0x11>;
			pinctrl-6 = <0x12>;

			rfctl16 {
				pins = "QOGIRL6_RFCTL16";
				function = "func4";
				phandle = <0x0c>;
			};

			rfctl3 {
				pins = "QOGIRL6_RFCTL3";
				function = "func4";
				phandle = <0x0d>;
			};

			rfctl5 {
				pins = "QOGIRL6_RFCTL5";
				function = "func4";
				phandle = <0x0e>;
			};

			rfctl6 {
				pins = "QOGIRL6_RFCTL6";
				function = "func4";
				phandle = <0x0f>;
			};

			rfctl7 {
				pins = "QOGIRL6_RFCTL7";
				function = "func4";
				phandle = <0x10>;
			};

			keyin0 {
				pins = "QOGIRL6_KEYIN0";
				function = "func4";
				phandle = <0x11>;
			};

			bt_rfctl2 {
				pins = "QOGIRL6_BT_RFCTL2";
				function = "func4";
				phandle = <0x12>;
			};
		};
	};

	fragment@26 {
		target = <0xffffffff>;

		__overlay__ {
			#address-cells = <0x01>;
			#size-cells = <0x00>;

			heap@4 {
				reg = <0x04>;
				label = "carveout_fd";
				type = <0x02>;
				memory-region = <0x13>;
			};

			heap@7 {
				reg = <0x07>;
				label = "carveout_oemcrypto";
				type = <0x02>;
				memory-region = <0x14>;
			};
		};
	};

	fragment@27 {
		target = <0xffffffff>;

		__overlay__ {
			sprd,hw-channels = <0x02 0x18cc 0x03 0x18cc 0x0d 0x1854 0x0f 0x1874 0x11 0x1844 0x13 0x1844 0x15 0x1864 0x1e 0x1820 0x20 0x197c 0x21 0x1988 0x23 0x19b8 0x27 0x19ac>;
			sprd,hw-channels0 = <0x02 0x18cc 0x03 0x18cc 0x0d 0x1874 0x0f 0x1874 0x11 0x1844 0x13 0x1854 0x15 0x1864 0x1e 0x1820 0x20 0x197c 0x21 0x1988 0x23 0x19b8 0x27 0x19ac>;
			sprd,hw-channels1 = <0x02 0x18cc 0x03 0x18cc 0x0d 0x1854 0x0f 0x1874 0x11 0x1844 0x13 0x1844 0x15 0x1864 0x1e 0x1820 0x20 0x197c 0x21 0x1988 0x23 0x19b8 0x27 0x19ac>;
		};
	};

	__symbols__ {
		lcd_icnl9916_hlt_mipi_hd_90 = "/fragment/__overlay__/lcds/lcd_icnl9916_hlt_mipi_hd_90";
		lcd_icnl9916_hlt_mipi_hd_timing0 = "/fragment/__overlay__/lcds/lcd_icnl9916_hlt_mipi_hd_90/display-timings/timing0";
		lcd_icnl9916_hlt_mipi_hd_timing1 = "/fragment/__overlay__/lcds/lcd_icnl9916_hlt_mipi_hd_90/display-timings/timing1";
		lcd_icnl9916_lide_mipi_hd_90 = "/fragment/__overlay__/lcds/lcd_icnl9916_lide_mipi_hd_90";
		lcd_icnl9916_lide_mipi_hd_timing0 = "/fragment/__overlay__/lcds/lcd_icnl9916_lide_mipi_hd_90/display-timings/timing0";
		lcd_icnl9916_lide_mipi_hd_timing1 = "/fragment/__overlay__/lcds/lcd_icnl9916_lide_mipi_hd_90/display-timings/timing1";
		lcd_icnl9916_huayin_new_mipi_hdp = "/fragment/__overlay__/lcds/lcd_icnl9916_huayin_new_mipi_hdp";
		lcd_icnl9916_huayin_new_mipi_hdp_timing0 = "/fragment/__overlay__/lcds/lcd_icnl9916_huayin_new_mipi_hdp/display-timings/timing0";
		lcd_icnl9916_huayin_new_mipi_hdp_timing1 = "/fragment/__overlay__/lcds/lcd_icnl9916_huayin_new_mipi_hdp/display-timings/timing1";
		lcd_dummy_mipi_hd = "/fragment/__overlay__/lcds/lcd_dummy_mipi_hd";
		dummy_timing0 = "/fragment/__overlay__/lcds/lcd_dummy_mipi_hd/display-timings/timing0";
		wcn_btwf = "/fragment/__overlay__/cpwcn-btwf";
		wcn_gnss = "/fragment/__overlay__/cpwcn-gnss";
		pwm_backlight = "/fragment/__overlay__/sprd_backlight";
		bat = "/fragment/__overlay__/battery";
		tboard_thermistor = "/fragment/__overlay__/thermal-sensor";
		pa_thermistor = "/fragment/__overlay__/pa-sensor";
		chg_thermistor = "/fragment/__overlay__/chg-sensor";
		sipc_wcn = "/fragment@0/__overlay__/core@3";
		sipc_gnss = "/fragment@0/__overlay__/core@4";
		sttygnss0 = "/fragment@0/__overlay__/core@4/channel@4";
		wcn_reserved = "/fragment@2/__overlay__/wcn-mem@87000000";
		logo_reserved = "/fragment@2/__overlay__/logobuffer@9e000000";
		oemcrypto_reserved = "/fragment@2/__overlay__/oemcrypto@b6100000";
		widevine_reserved = "/fragment@2/__overlay__/widevine@df400000";
		fd_reserved = "/fragment@2/__overlay__/faceid-mem@ffa70000";
		bd_thmzone = "/fragment@3/__overlay__/board-thmzone";
		pa_thmzone = "/fragment@3/__overlay__/pa-thmzone";
		chg_thmzone = "/fragment@3/__overlay__/chg-thmzone";
		sensor_main = "/fragment@4/__overlay__/sensor-main@20";
		sensor_sub = "/fragment@5/__overlay__/sensor-sub@5a";
		sensor_main2 = "/fragment@6/__overlay__/sensor-main2@20";
		sensor_sub2 = "/fragment@6/__overlay__/sensor-sub2@41";
		sensor_main3 = "/fragment@6/__overlay__/sensor-main3@61";
		eta6937_slave_chg = "/fragment@7/__overlay__/charger@6a";
		flash_ic = "/fragment@7/__overlay__/flash-ic@63";
		bq2560x_chg = "/fragment@8/__overlay__/charger@6b";
		vddvbus = "/fragment@8/__overlay__/charger@6b/otg-vbus";
		usb_con = "/fragment@23/__overlay__/connector";
		gpio_8 = "/fragment@25/__overlay__/rfctl16";
		gpio_22 = "/fragment@25/__overlay__/rfctl3";
		gpio_24 = "/fragment@25/__overlay__/rfctl5";
		gpio_25 = "/fragment@25/__overlay__/rfctl6";
		gpio_26 = "/fragment@25/__overlay__/rfctl7";
		gpio_124 = "/fragment@25/__overlay__/keyin0";
		gpio_175 = "/fragment@25/__overlay__/bt_rfctl2";
	};

	__fixups__ {
		aon_apb_regs = "/fragment/__overlay__/cpwcn-btwf:sprd,syscon-ap-apb:0", "/fragment/__overlay__/cpwcn-gnss:sprd,syscon-ap-apb:0";
		pmu_apb_regs = "/fragment/__overlay__/cpwcn-btwf:sprd,syscon-ap-pmu:0", "/fragment/__overlay__/cpwcn-gnss:sprd,syscon-ap-pmu:0";
		wcncp_aon_apb_regs = "/fragment/__overlay__/cpwcn-btwf:sprd,syscon-wcn-aon-apb:0", "/fragment/__overlay__/cpwcn-gnss:sprd,syscon-wcn-aon-apb:0";
		wcncp_aon_ahb_regs = "/fragment/__overlay__/cpwcn-btwf:sprd,syscon-wcn-aon-ahb:0", "/fragment/__overlay__/cpwcn-gnss:sprd,syscon-wcn-aon-ahb:0";
		pub_apb_regs = "/fragment/__overlay__/cpwcn-btwf:sprd,syscon-ap-pub-apb:0", "/fragment/__overlay__/cpwcn-gnss:sprd,syscon-ap-pub-apb:0";
		wcncp_btwf_ahb_regs = "/fragment/__overlay__/cpwcn-btwf:sprd,syscon-wcn-btwf-ahb:0";
		vddwcn = "/fragment/__overlay__/cpwcn-btwf:vddwcn-supply:0", "/fragment/__overlay__/cpwcn-gnss:vddwcn-supply:0";
		vddsim2 = "/fragment/__overlay__/cpwcn-btwf:dcxo1v8-supply:0", "/fragment/__overlay__/cpwcn-gnss:dcxo1v8-supply:0";
		vddwifipa = "/fragment/__overlay__/cpwcn-btwf:vddwifipa-supply:0";
		ap_gpio = "/fragment/__overlay__/cpwcn-btwf:merlion-chip-en-gpios:0", "/fragment/__overlay__/cpwcn-btwf:merlion-rst-gpios:0", "/fragment/__overlay__/cpwcn-btwf:xtal-26m-type-sel-gpios:0", "/fragment/__overlay__/cpwcn-gnss:merlion-chip-en-gpios:0", "/fragment/__overlay__/cpwcn-gnss:merlion-rst-gpios:0", "/fragment/__overlay__/cpwcn-gnss:xtal-26m-type-sel-gpios:0", "/fragment/__overlay__/fingerprint@0:fpreset-gpios:0", "/fragment/__overlay__/gpio-keys/key-volumedown:gpios:0", "/fragment/__overlay__/audio-voice-trig:irq_gpio:0", "/fragment@4/__overlay__/sensor-main@20:dvdd-gpios:0", "/fragment@4/__overlay__/sensor-main@20:avdd-gpios:0", "/fragment@4/__overlay__/sensor-main@20:reset-gpios:0", "/fragment@4/__overlay__/sensor-main@20:power-down-gpios:0", "/fragment@5/__overlay__/sensor-sub@5a:dvdd-gpios:0", "/fragment@5/__overlay__/sensor-sub@5a:avdd-gpios:0", "/fragment@5/__overlay__/sensor-sub@5a:reset-gpios:0", "/fragment@5/__overlay__/sensor-sub@5a:power-down-gpios:0", "/fragment@6/__overlay__/sensor-main2@20:power-down-gpios:0", "/fragment@6/__overlay__/sensor-main2@20:reset-gpios:0", "/fragment@7/__overlay__/charger@6a:enable-gpio:0", "/fragment@7/__overlay__/flash-ic@63:flash-torch-en-gpios:0", "/fragment@7/__overlay__/flash-ic@63:flash-chip-en-gpios:0", "/fragment@9/__overlay__/chipone_tddi@0:interrupt-parent:0", "/fragment@9/__overlay__/chipone_tddi@0:chipone,irq-gpio:0", "/fragment@9/__overlay__/chipone_tddi@0:chipone,rst-gpio:0", "/fragment@9/__overlay__/focaltech@1:interrupt-parent:0", "/fragment@9/__overlay__/focaltech@1:focaltech,reset-gpio:0", "/fragment@9/__overlay__/focaltech@1:focaltech,irq-gpio:0", "/fragment@17/__overlay__:sprd,spk-ext-pa-gpio:0", "/fragment@20/__overlay__:avdd-gpio:0", "/fragment@20/__overlay__:avee-gpio:0", "/fragment@20/__overlay__:reset-gpio:0";
		wcn_alpha = "/fragment/__overlay__/cpwcn-btwf:nvmem-cells:0", "/fragment/__overlay__/cpwcn-gnss:nvmem-cells:0";
		wcncp_gnss_ahb_regs = "/fragment/__overlay__/cpwcn-gnss:sprd,syscon-wcn-gnss-ahb:0";
		pwms = "/fragment/__overlay__/sprd_backlight:pwms:0";
		eic_async = "/fragment/__overlay__/fingerprint@0:fpint-gpios:0";
		pmic_eic = "/fragment/__overlay__/gpio-keys/key-volumeup:gpios:0", "/fragment/__overlay__/gpio-keys/key-power:gpios:0";
		hsphy = "/fragment/__overlay__/charger-manager:phys:0", "/fragment@7/__overlay__/charger@6a:phys:0", "/fragment@8/__overlay__/charger@6b:phys:0", "/fragment@10:target:0", "/fragment@19/__overlay__:phys:0", "/fragment@22/__overlay__:phys:0";
		pmic_typec = "/fragment/__overlay__/charger-manager:extcon:0", "/fragment@7/__overlay__/charger@6a:extcon:0", "/fragment@8/__overlay__/charger@6b:extcon:0", "/fragment@11/__overlay__:extcon:4";
		pmic_pd = "/fragment/__overlay__/charger-manager:extcon:4", "/fragment@23:target:0";
		pmic_adc = "/fragment/__overlay__/thermal-sensor:io-channels:0", "/fragment/__overlay__/pa-sensor:io-channels:0", "/fragment/__overlay__/chg-sensor:io-channels:0";
		uid_start = "/fragment/__overlay__/sprd_uid:nvmem-cells:0";
		uid_end = "/fragment/__overlay__/sprd_uid:nvmem-cells:4";
		sipc = "/fragment@0:target:0";
		mailbox = "/fragment@0/__overlay__/core@3:mboxes:0", "/fragment@0/__overlay__/core@4:mboxes:0";
		chosen = "/fragment@1:target:0";
		reserved_memory = "/fragment@2:target:0";
		thm_zone = "/fragment@3:target:0";
		i2c0 = "/fragment@4:target:0";
		mm_clk = "/fragment@4/__overlay__/sensor-main@20:clocks:0", "/fragment@5/__overlay__/sensor-sub@5a:clocks:0", "/fragment@6/__overlay__/sensor-main2@20:clocks:0", "/fragment@6/__overlay__/sensor-sub2@41:clocks:0", "/fragment@6/__overlay__/sensor-main3@61:clocks:0";
		mm_gate = "/fragment@4/__overlay__/sensor-main@20:clocks:8", "/fragment@5/__overlay__/sensor-sub@5a:clocks:8", "/fragment@6/__overlay__/sensor-main2@20:clocks:8", "/fragment@6/__overlay__/sensor-sub2@41:clocks:8", "/fragment@6/__overlay__/sensor-main3@61:clocks:8";
		pll1 = "/fragment@4/__overlay__/sensor-main@20:clocks:16", "/fragment@4/__overlay__/sensor-main@20:clocks:24", "/fragment@4/__overlay__/sensor-main@20:clocks:32", "/fragment@5/__overlay__/sensor-sub@5a:clocks:16", "/fragment@5/__overlay__/sensor-sub@5a:clocks:24", "/fragment@5/__overlay__/sensor-sub@5a:clocks:32", "/fragment@6/__overlay__/sensor-main2@20:clocks:16", "/fragment@6/__overlay__/sensor-main2@20:clocks:24", "/fragment@6/__overlay__/sensor-main2@20:clocks:32", "/fragment@6/__overlay__/sensor-sub2@41:clocks:16", "/fragment@6/__overlay__/sensor-sub2@41:clocks:24", "/fragment@6/__overlay__/sensor-sub2@41:clocks:32", "/fragment@6/__overlay__/sensor-main3@61:clocks:16", "/fragment@6/__overlay__/sensor-main3@61:clocks:24", "/fragment@6/__overlay__/sensor-main3@61:clocks:32";
		ext_26m = "/fragment@4/__overlay__/sensor-main@20:clocks:40", "/fragment@5/__overlay__/sensor-sub@5a:clocks:40", "/fragment@6/__overlay__/sensor-main2@20:clocks:40", "/fragment@6/__overlay__/sensor-sub2@41:clocks:40", "/fragment@6/__overlay__/sensor-main3@61:clocks:40";
		vddcamio = "/fragment@4/__overlay__/sensor-main@20:vddio-supply:0", "/fragment@5/__overlay__/sensor-sub@5a:vddio-supply:0", "/fragment@6/__overlay__/sensor-main2@20:vddio-supply:0";
		vddcama0 = "/fragment@4/__overlay__/sensor-main@20:vddcama-supply:0", "/fragment@5/__overlay__/sensor-sub@5a:vddcama-supply:0";
		vddcamd0 = "/fragment@4/__overlay__/sensor-main@20:vddcamd-supply:0";
		vddcammot = "/fragment@4/__overlay__/sensor-main@20:vddcammot-supply:0", "/fragment@5/__overlay__/sensor-sub@5a:vddcammot-supply:0", "/fragment@6/__overlay__/sensor-main2@20:vddcammot-supply:0", "/fragment@6/__overlay__/sensor-sub2@41:vddcammot-supply:0", "/fragment@6/__overlay__/sensor-main3@61:vddcammot-supply:0";
		csi0 = "/fragment@4/__overlay__/sensor-main@20:csi:0";
		mm_domain = "/fragment@4/__overlay__/sensor-main@20:power-domains:0", "/fragment@5/__overlay__/sensor-sub@5a:power-domains:0", "/fragment@6/__overlay__/sensor-main2@20:power-domains:0";
		i2c6 = "/fragment@5:target:0";
		vddcamd1 = "/fragment@5/__overlay__/sensor-sub@5a:vddcamd-supply:0", "/fragment@6/__overlay__/sensor-main2@20:vddcamd-supply:0", "/fragment@6/__overlay__/sensor-sub2@41:vddcamd-supply:0", "/fragment@6/__overlay__/sensor-main3@61:vddcamd-supply:0";
		csi1 = "/fragment@5/__overlay__/sensor-sub@5a:csi:0", "/fragment@6/__overlay__/sensor-main2@20:csi:0", "/fragment@6/__overlay__/sensor-sub2@41:csi:0", "/fragment@6/__overlay__/sensor-main3@61:csi:0";
		i2c1 = "/fragment@6:target:0";
		vddcama1 = "/fragment@6/__overlay__/sensor-main2@20:vddcama-supply:0", "/fragment@6/__overlay__/sensor-sub2@41:vddcama-supply:0", "/fragment@6/__overlay__/sensor-main3@61:vddcama-supply:0";
		i2c4 = "/fragment@7:target:0";
		i2c5 = "/fragment@8:target:0";
		spi3 = "/fragment@9:target:0";
		vddusb33 = "/fragment@10/__overlay__:vdd-supply:0";
		extcon_gpio = "/fragment@10/__overlay__:extcon:0", "/fragment@11/__overlay__:extcon:0";
		usb = "/fragment@11:target:0";
		sdio0 = "/fragment@12:target:0";
		eic_sync = "/fragment@12/__overlay__:cd-gpios:0";
		i2c3 = "/fragment@13:target:0";
		aon_i2c0 = "/fragment@14:target:0";
		sprd_headset = "/fragment@15:target:0";
		pdm_dmic = "/fragment@16:target:0";
		sound_vbc_v4_sprd_codec = "/fragment@17:target:0";
		vddldo0 = "/fragment@18:target:0";
		pmic_fgu = "/fragment@19:target:0";
		panel = "/fragment@20:target:0";
		dpu = "/fragment@21:target:0";
		pmic_fchg = "/fragment@22:target:0";
		ddr_dfs = "/fragment@24:target:0";
		pin_controller = "/fragment@25:target:0";
		ion = "/fragment@26:target:0";
		adi_bus = "/fragment@27:target:0";
	};

	__local_fixups__ {

		fragment {

			__overlay__ {

				lcds {

					lcd_icnl9916_hlt_mipi_hd_90 {

						display-timings {
							native-mode = <0x00>;
						};
					};

					lcd_icnl9916_lide_mipi_hd_90 {

						display-timings {
							native-mode = <0x00>;
						};
					};

					lcd_icnl9916_huayin_new_mipi_hdp {

						display-timings {
							native-mode = <0x00>;
						};
					};

					lcd_dummy_mipi_hd {

						display-timings {
							native-mode = <0x00>;
						};
					};
				};

				charger-manager {
					monitored-battery = <0x00>;
				};
			};
		};

		fragment@3 {

			__overlay__ {

				board-thmzone {
					thermal-sensors = <0x00>;
				};

				pa-thmzone {
					thermal-sensors = <0x00>;
				};

				chg-thmzone {
					thermal-sensors = <0x00>;
				};
			};
		};

		fragment@7 {

			__overlay__ {

				charger@6a {
					monitored-battery = <0x00>;
				};
			};
		};

		fragment@8 {

			__overlay__ {

				charger@6b {
					monitored-battery = <0x00>;
				};
			};
		};

		fragment@11 {

			__overlay__ {
				vbus-supply = <0x00>;
			};
		};

		fragment@19 {

			__overlay__ {
				monitored-battery = <0x00>;
			};
		};

		fragment@20 {

			__overlay__ {
				sprd,backlight = <0x00>;
			};
		};

		fragment@21 {

			__overlay__ {
				sprd,logo-memory = <0x00>;
				sprd,backlight = <0x00>;
			};
		};

		fragment@25 {

			__overlay__ {
				pinctrl-0 = <0x00>;
				pinctrl-1 = <0x00>;
				pinctrl-2 = <0x00>;
				pinctrl-3 = <0x00>;
				pinctrl-4 = <0x00>;
				pinctrl-5 = <0x00>;
				pinctrl-6 = <0x00>;
			};
		};

		fragment@26 {

			__overlay__ {

				heap@4 {
					memory-region = <0x00>;
				};

				heap@7 {
					memory-region = <0x00>;
				};
			};
		};
	};
};
